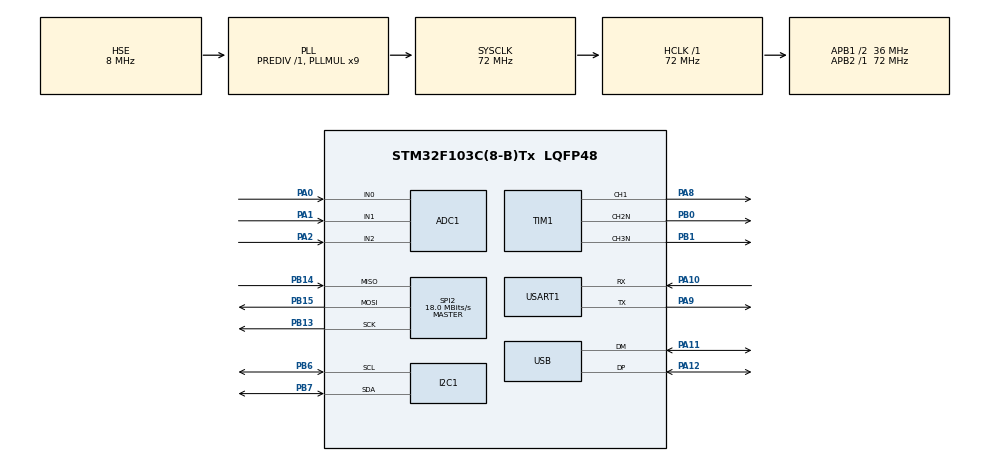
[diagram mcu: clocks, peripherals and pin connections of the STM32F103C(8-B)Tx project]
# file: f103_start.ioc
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ADC1.Channel-0\#ChannelRegularConversion=ADC_CHANNEL_0
ADC1.NbrOfConversionFlag=1
ADC1.Rank-0\#ChannelRegularConversion=1
ADC1.SamplingTime-0\#ChannelRegularConversion=ADC_SAMPLETIME_1CYCLE_5
ADC1.master=1
FREERTOS.Tasks01=defaultTask,0,128,StartDefaultTask,Default,NULL,Dynamic,NULL,NULL
Mcu.Family=STM32F1
Mcu.Name=STM32F103C(8-B)Tx
Mcu.Package=LQFP48
NVIC.PriorityGroup=NVIC_PRIORITYGROUP_4
NVIC.USB_LP_CAN1_RX0_IRQn=true\:5\:0\:false\:false\:true\:true\:false\:true
PA0-WKUP.Signal=ADCx_IN0
PA1.Signal=ADCx_IN1
PA10.Mode=Asynchronous
PA10.Signal=USART1_RX
PA11.Mode=Device
PA11.Signal=USB_DM
PA12.Mode=Device
PA12.Signal=USB_DP
PA13.Mode=JTAG_5_pins
PA13.Signal=SYS_JTMS-SWDIO
PA14.Mode=JTAG_5_pins
PA14.Signal=SYS_JTCK-SWCLK
PA15.Mode=JTAG_5_pins
PA15.Signal=SYS_JTDI
PA2.Signal=ADCx_IN2
PA8.Signal=S_TIM1_CH1
PA9.Mode=Asynchronous
PA9.Signal=USART1_TX
PB0.Mode=Output Compare2 CH2N
PB0.Signal=TIM1_CH2N
PB1.Mode=Output Compare3 CH3N
PB1.Signal=TIM1_CH3N
PB13.Mode=Full_Duplex_Master
PB13.Signal=SPI2_SCK
PB14.Mode=Full_Duplex_Master
PB14.Signal=SPI2_MISO
PB15.Mode=Full_Duplex_Master
PB15.Signal=SPI2_MOSI
PB3.Mode=JTAG_5_pins
PB3.Signal=SYS_JTDO-TRACESWO
PB4.Mode=JTAG_5_pins
PB4.Signal=SYS_NJTRST
PB6.Mode=I2C
PB6.Signal=I2C1_SCL
PB7.Mode=I2C
PB7.Signal=I2C1_SDA
PC14-OSC32_IN.Mode=LSE-External-Oscillator
PC14-OSC32_IN.Signal=RCC_OSC32_IN
PC15-OSC32_OUT.Mode=LSE-External-Oscillator
PC15-OSC32_OUT.Signal=RCC_OSC32_OUT
PD0-OSC_IN.Mode=HSE-External-Oscillator
PD0-OSC_IN.Signal=RCC_OSC_IN
PD1-OSC_OUT.Mode=HSE-External-Oscillator
PD1-OSC_OUT.Signal=RCC_OSC_OUT
ProjectManager.HeapSize=0x200
ProjectManager.StackSize=0x400
ProjectManager.TargetToolchain=STM32CubeIDE
RCC.ADCPresc=RCC_ADCPCLK2_DIV6
RCC.AHBFreq_Value=72000000
RCC.APB1CLKDivider=RCC_HCLK_DIV2
RCC.APB1Freq_Value=36000000
RCC.APB1TimFreq_Value=72000000
RCC.APB2Freq_Value=72000000
RCC.APB2TimFreq_Value=72000000
RCC.HCLKFreq_Value=72000000
RCC.PLLMUL=RCC_PLL_MUL9
RCC.RTCClockSelection=RCC_RTCCLKSOURCE_LSE
RCC.SYSCLKFreq_VALUE=72000000
RCC.SYSCLKSource=RCC_SYSCLKSOURCE_PLLCLK
RCC.USBFreq_Value=48000000
RCC.USBPrescaler=RCC_USBCLKSOURCE_PLL_DIV1_5
SH.ADCx_IN0.0=ADC1_IN0,IN0
SH.ADCx_IN1.0=ADC1_IN1,IN1
SH.ADCx_IN2.0=ADC1_IN2,IN2
SH.S_TIM1_CH1.0=TIM1_CH1,PWM Generation1 CH1
SPI2.CalculateBaudRate=18.0 MBits/s
SPI2.Direction=SPI_DIRECTION_2LINES
SPI2.Mode=SPI_MODE_MASTER
SPI2.VirtualType=VM_MASTER
TIM1.Channel-Output\ Compare2\ CH2N=TIM_CHANNEL_2
TIM1.Channel-Output\ Compare3\ CH3N=TIM_CHANNEL_3
TIM1.Channel-PWM\ Generation1\ CH1=TIM_CHANNEL_1
USART1.VirtualMode=VM_ASYNC
USB_DEVICE.CLASS_NAME_FS=CDC
USB_DEVICE.VirtualMode=Cdc
USB_DEVICE.VirtualModeFS=Cdc_FS
VP_CRC_VS_CRC.Mode=CRC_Activate
VP_FREERTOS_VS_CMSIS_V1.Mode=CMSIS_V1
VP_RTC_VS_RTC_Activate.Mode=RTC_Enabled
VP_TIM1_VS_ClockSourceINT.Mode=Internal
VP_USB_DEVICE_VS_USB_DEVICE_CDC_FS.Mode=CDC_FS
board=custom

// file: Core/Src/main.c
/* USER CODE BEGIN Header */
/**
  ******************************************************************************
  * @file           : main.c
  * @brief          : Main program body
  ******************************************************************************
  * @attention
  *
  * <h2><center>&copy; Copyright (c) 2020 STMicroelectronics.
  * All rights reserved.</center></h2>
  *
  * This software component is licensed by ST under BSD 3-Clause license,
  * the "License"; You may not use this file except in compliance with the
  * License. You may obtain a copy of the License at:
  *                        opensource.org/licenses/BSD-3-Clause
  *
  ******************************************************************************
  */
/* USER CODE END Header */

#include "main.h"
#include "cmsis_os.h"
#include "usb_device.h"

ADC_HandleTypeDef hadc1;

CRC_HandleTypeDef hcrc;

I2C_HandleTypeDef hi2c1;

RTC_HandleTypeDef hrtc;

SPI_HandleTypeDef hspi2;

TIM_HandleTypeDef htim1;

UART_HandleTypeDef huart1;

osThreadId defaultTaskHandle;

void SystemClock_Config(void);
static void MX_GPIO_Init(void);
static void MX_ADC1_Init(void);
static void MX_CRC_Init(void);
static void MX_I2C1_Init(void);
static void MX_RTC_Init(void);
static void MX_SPI2_Init(void);
static void MX_TIM1_Init(void);
static void MX_USART1_UART_Init(void);
void StartDefaultTask(void const * argument);

int main(void)
{
  /* USER CODE BEGIN 1 */
  // test pozzi commit
  /* USER CODE END 1 */

  /* MCU Configuration--------------------------------------------------------*/

  /* Reset of all peripherals, Initializes the Flash interface and the Systick. */
  HAL_Init();

  /* Configure the system clock */
  SystemClock_Config();

  /* Initialize all configured peripherals */
  MX_GPIO_Init();
  MX_ADC1_Init();
  MX_CRC_Init();
  MX_I2C1_Init();
  MX_RTC_Init();
  MX_SPI2_Init();
  MX_TIM1_Init();
  MX_USART1_UART_Init();

  /* Create the thread(s) */
  /* definition and creation of defaultTask */
  osThreadDef(defaultTask, StartDefaultTask, osPriorityNormal, 0, 128);
  defaultTaskHandle = osThreadCreate(osThread(defaultTask), NULL);

  /* Start scheduler */
  osKernelStart();

  /* We should never get here as control is now taken by the scheduler */

  /* Infinite loop */
  while (1)
  {

  }
}

void SystemClock_Config(void)
{
  RCC_OscInitTypeDef RCC_OscInitStruct = {0};
  RCC_ClkInitTypeDef RCC_ClkInitStruct = {0};
  RCC_PeriphCLKInitTypeDef PeriphClkInit = {0};

  /** Initializes the CPU, AHB and APB busses clocks
  */
  RCC_OscInitStruct.OscillatorType = RCC_OSCILLATORTYPE_HSE|RCC_OSCILLATORTYPE_LSE;
  RCC_OscInitStruct.HSEState = RCC_HSE_ON;
  RCC_OscInitStruct.HSEPredivValue = RCC_HSE_PREDIV_DIV1;
  RCC_OscInitStruct.LSEState = RCC_LSE_ON;
  RCC_OscInitStruct.HSIState = RCC_HSI_ON;
  RCC_OscInitStruct.PLL.PLLState = RCC_PLL_ON;
  RCC_OscInitStruct.PLL.PLLSource = RCC_PLLSOURCE_HSE;
  RCC_OscInitStruct.PLL.PLLMUL = RCC_PLL_MUL9;
  if (HAL_RCC_OscConfig(&RCC_OscInitStruct) != HAL_OK)
  {
    Error_Handler();
  }
  /** Initializes the CPU, AHB and APB busses clocks
  */
  RCC_ClkInitStruct.ClockType = RCC_CLOCKTYPE_HCLK|RCC_CLOCKTYPE_SYSCLK
                              |RCC_CLOCKTYPE_PCLK1|RCC_CLOCKTYPE_PCLK2;
  RCC_ClkInitStruct.SYSCLKSource = RCC_SYSCLKSOURCE_PLLCLK;
  RCC_ClkInitStruct.AHBCLKDivider = RCC_SYSCLK_DIV1;
  RCC_ClkInitStruct.APB1CLKDivider = RCC_HCLK_DIV2;
  RCC_ClkInitStruct.APB2CLKDivider = RCC_HCLK_DIV1;

  if (HAL_RCC_ClockConfig(&RCC_ClkInitStruct, FLASH_LATENCY_2) != HAL_OK)
  {
    Error_Handler();
  }
  PeriphClkInit.PeriphClockSelection = RCC_PERIPHCLK_RTC|RCC_PERIPHCLK_ADC
                              |RCC_PERIPHCLK_USB;
  PeriphClkInit.RTCClockSelection = RCC_RTCCLKSOURCE_LSE;
  PeriphClkInit.AdcClockSelection = RCC_ADCPCLK2_DIV6;
  PeriphClkInit.UsbClockSelection = RCC_USBCLKSOURCE_PLL_DIV1_5;
  if (HAL_RCCEx_PeriphCLKConfig(&PeriphClkInit) != HAL_OK)
  {
    Error_Handler();
  }
}

static void MX_ADC1_Init(void)
{

  ADC_ChannelConfTypeDef sConfig = {0};

  /** Common config
  */
  hadc1.Instance = ADC1;
  hadc1.Init.ScanConvMode = ADC_SCAN_DISABLE;
  hadc1.Init.ContinuousConvMode = DISABLE;
  hadc1.Init.DiscontinuousConvMode = DISABLE;
  hadc1.Init.ExternalTrigConv = ADC_SOFTWARE_START;
  hadc1.Init.DataAlign = ADC_DATAALIGN_RIGHT;
  hadc1.Init.NbrOfConversion = 1;
  if (HAL_ADC_Init(&hadc1) != HAL_OK)
  {
    Error_Handler();
  }
  /** Configure Regular Channel
  */
  sConfig.Channel = ADC_CHANNEL_0;
  sConfig.Rank = ADC_REGULAR_RANK_1;
  sConfig.SamplingTime = ADC_SAMPLETIME_1CYCLE_5;
  if (HAL_ADC_ConfigChannel(&hadc1, &sConfig) != HAL_OK)
  {
    Error_Handler();
  }

}

static void MX_CRC_Init(void)
{

  hcrc.Instance = CRC;
  if (HAL_CRC_Init(&hcrc) != HAL_OK)
  {
    Error_Handler();
  }

}

static void MX_I2C1_Init(void)
{

  hi2c1.Instance = I2C1;
  hi2c1.Init.ClockSpeed = 100000;
  hi2c1.Init.DutyCycle = I2C_DUTYCYCLE_2;
  hi2c1.Init.OwnAddress1 = 0;
  hi2c1.Init.AddressingMode = I2C_ADDRESSINGMODE_7BIT;
  hi2c1.Init.DualAddressMode = I2C_DUALADDRESS_DISABLE;
  hi2c1.Init.OwnAddress2 = 0;
  hi2c1.Init.GeneralCallMode = I2C_GENERALCALL_DISABLE;
  hi2c1.Init.NoStretchMode = I2C_NOSTRETCH_DISABLE;
  if (HAL_I2C_Init(&hi2c1) != HAL_OK)
  {
    Error_Handler();
  }

}

static void MX_RTC_Init(void)
{

  /** Initialize RTC Only
  */
  hrtc.Instance = RTC;
  hrtc.Init.AsynchPrediv = RTC_AUTO_1_SECOND;
  hrtc.Init.OutPut = RTC_OUTPUTSOURCE_ALARM;
  if (HAL_RTC_Init(&hrtc) != HAL_OK)
  {
    Error_Handler();
  }

}

static void MX_SPI2_Init(void)
{

  /* SPI2 parameter configuration*/
  hspi2.Instance = SPI2;
  hspi2.Init.Mode = SPI_MODE_MASTER;
  hspi2.Init.Direction = SPI_DIRECTION_2LINES;
  hspi2.Init.DataSize = SPI_DATASIZE_8BIT;
  hspi2.Init.CLKPolarity = SPI_POLARITY_LOW;
  hspi2.Init.CLKPhase = SPI_PHASE_1EDGE;
  hspi2.Init.NSS = SPI_NSS_SOFT;
  hspi2.Init.BaudRatePrescaler = SPI_BAUDRATEPRESCALER_2;
  hspi2.Init.FirstBit = SPI_FIRSTBIT_MSB;
  hspi2.Init.TIMode = SPI_TIMODE_DISABLE;
  hspi2.Init.CRCCalculation = SPI_CRCCALCULATION_DISABLE;
  hspi2.Init.CRCPolynomial = 10;
  if (HAL_SPI_Init(&hspi2) != HAL_OK)
  {
    Error_Handler();
  }

}

static void MX_TIM1_Init(void)
{

  TIM_ClockConfigTypeDef sClockSourceConfig = {0};
  TIM_MasterConfigTypeDef sMasterConfig = {0};
  TIM_OC_InitTypeDef sConfigOC = {0};
  TIM_BreakDeadTimeConfigTypeDef sBreakDeadTimeConfig = {0};

  htim1.Instance = TIM1;
  htim1.Init.Prescaler = 0;
  htim1.Init.CounterMode = TIM_COUNTERMODE_UP;
  htim1.Init.Period = 0;
  htim1.Init.ClockDivision = TIM_CLOCKDIVISION_DIV1;
  htim1.Init.RepetitionCounter = 0;
  htim1.Init.AutoReloadPreload = TIM_AUTORELOAD_PRELOAD_DISABLE;
  if (HAL_TIM_Base_Init(&htim1) != HAL_OK)
  {
    Error_Handler();
  }
  sClockSourceConfig.ClockSource = TIM_CLOCKSOURCE_INTERNAL;
  if (HAL_TIM_ConfigClockSource(&htim1, &sClockSourceConfig) != HAL_OK)
  {
    Error_Handler();
  }
  if (HAL_TIM_PWM_Init(&htim1) != HAL_OK)
  {
    Error_Handler();
  }
  if (HAL_TIM_OC_Init(&htim1) != HAL_OK)
  {
    Error_Handler();
  }
  sMasterConfig.MasterOutputTrigger = TIM_TRGO_RESET;
  sMasterConfig.MasterSlaveMode = TIM_MASTERSLAVEMODE_DISABLE;
  if (HAL_TIMEx_MasterConfigSynchronization(&htim1, &sMasterConfig) != HAL_OK)
  {
    Error_Handler();
  }
  sConfigOC.OCMode = TIM_OCMODE_PWM1;
  sConfigOC.Pulse = 0;
  sConfigOC.OCPolarity = TIM_OCPOLARITY_HIGH;
  sConfigOC.OCNPolarity = TIM_OCNPOLARITY_HIGH;
  sConfigOC.OCFastMode = TIM_OCFAST_DISABLE;
  sConfigOC.OCIdleState = TIM_OCIDLESTATE_RESET;
  sConfigOC.OCNIdleState = TIM_OCNIDLESTATE_RESET;
  if (HAL_TIM_PWM_ConfigChannel(&htim1, &sConfigOC, TIM_CHANNEL_1) != HAL_OK)
  {
    Error_Handler();
  }
  sConfigOC.OCMode = TIM_OCMODE_TIMING;
  if (HAL_TIM_OC_ConfigChannel(&htim1, &sConfigOC, TIM_CHANNEL_2) != HAL_OK)
  {
    Error_Handler();
  }
  if (HAL_TIM_OC_ConfigChannel(&htim1, &sConfigOC, TIM_CHANNEL_3) != HAL_OK)
  {
    Error_Handler();
  }
  sBreakDeadTimeConfig.OffStateRunMode = TIM_OSSR_DISABLE;
  sBreakDeadTimeConfig.OffStateIDLEMode = TIM_OSSI_DISABLE;
  sBreakDeadTimeConfig.LockLevel = TIM_LOCKLEVEL_OFF;
  sBreakDeadTimeConfig.DeadTime = 0;
  sBreakDeadTimeConfig.BreakState = TIM_BREAK_DISABLE;
  sBreakDeadTimeConfig.BreakPolarity = TIM_BREAKPOLARITY_HIGH;
  sBreakDeadTimeConfig.AutomaticOutput = TIM_AUTOMATICOUTPUT_DISABLE;
  if (HAL_TIMEx_ConfigBreakDeadTime(&htim1, &sBreakDeadTimeConfig) != HAL_OK)
  {
    Error_Handler();
  }
  HAL_TIM_MspPostInit(&htim1);

}

static void MX_USART1_UART_Init(void)
{

  huart1.Instance = USART1;
  huart1.Init.BaudRate = 115200;
  huart1.Init.WordLength = UART_WORDLENGTH_8B;
  huart1.Init.StopBits = UART_STOPBITS_1;
  huart1.Init.Parity = UART_PARITY_NONE;
  huart1.Init.Mode = UART_MODE_TX_RX;
  huart1.Init.HwFlowCtl = UART_HWCONTROL_NONE;
  huart1.Init.OverSampling = UART_OVERSAMPLING_16;
  if (HAL_UART_Init(&huart1) != HAL_OK)
  {
    Error_Handler();
  }

}

static void MX_GPIO_Init(void)
{

  /* GPIO Ports Clock Enable */
  __HAL_RCC_GPIOC_CLK_ENABLE();
  __HAL_RCC_GPIOD_CLK_ENABLE();
  __HAL_RCC_GPIOA_CLK_ENABLE();
  __HAL_RCC_GPIOB_CLK_ENABLE();

}

void StartDefaultTask(void const * argument)
{
  /* init code for USB_DEVICE */
  MX_USB_DEVICE_Init();
  for(;;)
  {
    osDelay(1);
  }
}

void Error_Handler(void)
{
}

/************************ (C) COPYRIGHT STMicroelectronics *****END OF FILE****/
